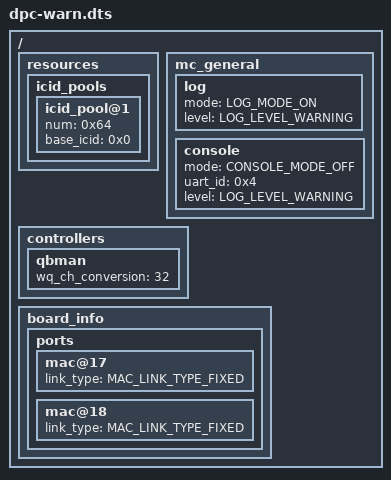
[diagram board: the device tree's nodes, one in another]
/* SPDX-License-Identifier: BSD-3-Clause */
/*
 * Copyright (c) 2021 TQ-Systems GmbH <oss@ew.tq-group.com>
 * D-82229 Seefeld, Germany.
 * Author: Gregor Herburger
 *
 * Copyright 2018 NXP
 *
 */

/*
* This DPC showcases one Linux configuration for lx2160a boards.
*/

/dts-v1/;

/ {

	resources {

		icid_pools {

			icid_pool@1 {
				num = <0x64>;
				base_icid = <0x0>;
			};
		};
	};

	mc_general {
		/* Configure the DDR log */
		log {
			mode = "LOG_MODE_ON";
			level = "LOG_LEVEL_WARNING";
		};
		/* Configure the UART log */
		/* If CONSOLE_MODE_ON all commands take longer time to execute! */
		console {
			mode = "CONSOLE_MODE_OFF";
			uart_id = <0x4>;
			level = "LOG_LEVEL_WARNING";
		};
	};

	controllers {

		qbman {
			/* Transform this number of 8-WQ channels into four times
			 * as many 2-WQ channels. This allows the creation of a
			 * larger number of DPCONs.
			 */
			wq_ch_conversion = <32>;
		};
	};

	board_info {
		ports {
			mac@17 {
				link_type = "MAC_LINK_TYPE_FIXED";
			};
			mac@18 {
				link_type = "MAC_LINK_TYPE_FIXED";
			};
		};
	};
};
